# nrf54lc10a_application register map
Vendor: Nordic Semiconductor; Series: nrf54l; File version: 1
CPU: CM33 r0p4, little endian, MPU, FPU, 3 interrupt priority bits, 270 interrupts, 4 SAU regions
Registers are 32-bit, read-write, reset 0x0 unless marked. A register's access mark holds for its fields unless they carry their own. Offsets are from the block's base; [hi:lo] are bit positions; lines under a group give offsets from that group; {n}, {i} and the like mark numbered series; 'fields as' and 'values as' point back to an identical list.

## GLOBAL_FICR_NS — Factory Information Configuration Registers
Base 0x00FFC000
0x300 INFO group — Device info
  0x00 CONFIGID ro reset 0xFFFFFFFF — Configuration identifier
    [15:0] HWID — Identification number for the HW
  {0x4+4j} DEVICEID[{j}] (j=0..1) ro reset 0xFFFFFFFF — Description collection: Device identifier
    [31:0] DEVICEID — 64 bit unique device identifier
  {0xC+4j} UUID[{j}] (j=0..3) ro reset 0xFFFFFFFF — Description collection: 128-bit Universally Unique IDentifier (UUID).
    [31:0] UUID — Device UUID [n].
  0x1C PART ro reset 0xFFFFFFFF — Part code
    [31:0] PART
      0x54BF10A=N54LC10A (nRF54LC10A); 0xFFFFFFFF=Unspecified
  0x20 VARIANT ro reset 0xFFFFFFFF — Function variant code, Hardware version code, and Production configuration code encoded as ASCII.
    [31:0] VARIANT — Function variant code, Hardware version code, and Production configuration code encoded as ASCII
      0x41414230=AAB0 (Example encoding for AAB0 - Function variant code AA, Hardware version code B, Production configuration code 0); 0xFFFFFFFF=Unspecified
  0x24 PACKAGE ro reset 0xFFFFFFFF — Package option
    [31:0] PACKAGE
      0xFFFFFFFF=Unspecified
  0x28 RAM ro reset 0xFFFFFFFF — RAM size (KB)
    [31:0] RAM
      192=K192 (192 kByte RAM); 0xFFFFFFFF=Unspecified
  0x2C RRAM ro reset 0xFFFFFFFF — RRAM size (KB)
    [31:0] RRAM
      0x3F4=K1012 (1012 KByte RRAM); 0xFFFFFFFF=Unspecified
{0x380+4i} ER[{i}] (i=0..3) ro reset 0xFFFFFFFF — Description collection: Common encryption root key, word n
  [31:0] ER — Encryption Root, word n
{0x390+4i} IR[{i}] (i=0..3) ro reset 0xFFFFFFFF — Description collection: Common identity root key, word n
  [31:0] IR — Identity Root, word n
0x3A0 DEVICEADDRTYPE ro reset 0xFFFFFFFF — Device address type
  [0] DEVICEADDRTYPE
    0=Public address; 1=Random address
{0x3A4+4i} DEVICEADDR[{i}] (i=0..1) ro reset 0xFFFFFFFF — Description collection: Device address n
  [31:0] DEVICEADDR — 48 bit device address
{0x400+8i} TRIMCNF[{i}] (i=0..63) group — Unspecified
  0x00 ADDR ro reset 0xFFFFFFFF — Description cluster: Address of the register which will be written
    [31:0] Address
  0x04 DATA ro reset 0xFFFFFFFF — Description cluster: Data to be written into the register
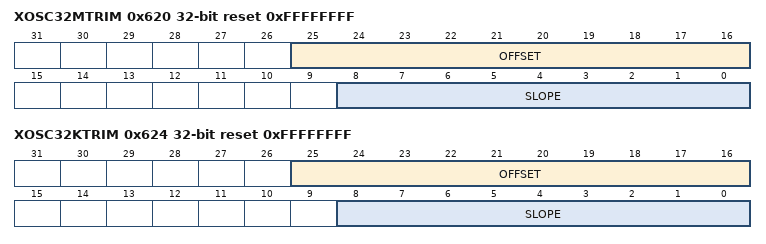
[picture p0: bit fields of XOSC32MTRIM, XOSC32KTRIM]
0x620 XOSC32MTRIM ro reset 0xFFFFFFFF — XOSC32M capacitor selection trim values
  [25:16] OFFSET — Offset trim factor on integer form
  [8:0] SLOPE — Slope trim factor on twos complement form
0x624 XOSC32KTRIM ro reset 0xFFFFFFFF — XOSC32K capacitor selection trim values
  fields as XOSC32MTRIM

## ICACHEDATA_S — CACHEDATA
Base 0x02F00000
{0x0+0x40*i} SET[{i}] (i=0..127) group — Unspecified
  {0x0+0x20*j} WAY[{j}] (j=0..1) group — Unspecified
    {0x0+8k} DU[{k}] (k=0..3) group — Unspecified
      {0x0+4l} DATA[{l}] (l=0..1) — Description collection: Cache data bits for DATA[q] in DU[p] (DataUnit) of SET[n], WAY[o].
        [31:0] Data ro

## ICACHEINFO_S — CACHEINFO
Base 0x02F10000
{0x0+8i} SET[{i}] (i=0..127) group — Unspecified
  {0x0+4j} WAY[{j}] (j=0..1) group — Unspecified
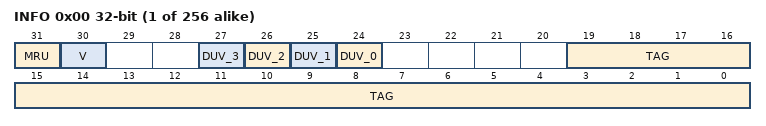
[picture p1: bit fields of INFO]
    0x00 INFO — Description cluster: Cache information for SET[n], WAY[o].
      [31] MRU ro — Most recently used way.
        0=Way0 was most recently used; 1=Way1 was most recently used
      [30] V ro — Line valid bit.
        0=Invalid cache line; 1=Valid cache line
      [n+24] DUV_{n} ro (n=0..3) — Data unit valid info.
        0=Invalid data unit; 1=Valid data unit
      [19:0] TAG ro — Cache tag.

## ICACHE_S — Cache
Base 0xE0082000
0x08 TASKS_INVALIDATECACHE wo — Invalidate the cache.
  [0] TASKS_INVALIDATECACHE
    1=Trigger task
0x14 TASKS_INVALIDATELINE wo — Invalidate the line.
  [0] TASKS_INVALIDATELINE
    1=Trigger task
0x20 TASKS_ERASE wo — Erase the cache.
  [0] TASKS_ERASE
    1=Trigger task
0x400 STATUS ro — Status of the cache activities.
  [0] READY — Ready status.
    0=Ready (Activity is done and ready for the next activity.); 1=Busy (Activity is in progress.)
0x404 ENABLE — Enable cache.
  [0] ENABLE — Enable cache
    0=Disabled (Disable cache); 1=Enabled (Enable cache)
0x410 LINEADDR — Memory address covered by the line to be maintained.
  [31:0] ADDR — Address.
0x414 PROFILING group — Unspecified
  0x00 ENABLE — Enable the profiling counters.
    [0] ENABLE — Enable the profiling counters
      0=Disable profiling; 1=Enable profiling
  0x04 CLEAR wo — Clear the profiling counters.
    [0] CLEAR — Clearing the profiling counters
      1=Clear the profiling counters
  0x08 HIT ro — The cache hit counter for cache region.
    [31:0] HITS — Number of cache hits
  0x0C MISS ro — The cache miss counter for cache region.
    [31:0] MISSES — Number of cache misses
  0x10 LMISS ro — The cache line miss counter for cache region.
    [31:0] LMISSES — Number of cache line misses
  0x14 READS ro — Number of reads for cache region.
  0x18 WRITES ro — Number of writes for cache region.
0x430 DEBUGLOCK rw-once — Lock debug mode.
  [0] DEBUGLOCK — Lock debug mode
    0=Unlocked (Debug mode unlocked); 1=Locked (Debug mode locked. Ignores any other value written.)
0x434 WRITELOCK — Lock cache updates.
  [0] WRITELOCK — Lock cache updates
    0=Unlocked (Cache updates unlocked); 1=Locked (Cache updates locked)

## Notices in the file
Copyright (c) 2010 - 2026, Nordic Semiconductor ASA All rights reserved.
SPDX-License-Identifier: BSD-3-Clause
Redistribution and use in source and binary forms, with or without
modification, are permitted provided that the following conditions are met:
1. Redistributions of source code must retain the above copyright notice, this
list of conditions and the following disclaimer.
2. Redistributions in binary form must reproduce the above copyright
notice, this list of conditions and the following disclaimer in the
documentation and/or other materials provided with the distribution.
3. Neither the name of Nordic Semiconductor ASA nor the names of its
contributors may be used to endorse or promote products derived from this
software without specific prior written permission.
THIS SOFTWARE IS PROVIDED BY THE COPYRIGHT HOLDERS AND CONTRIBUTORS "AS IS"
AND ANY EXPRESS OR IMPLIED WARRANTIES, INCLUDING, BUT NOT LIMITED TO, THE
IMPLIED WARRANTIES OF MERCHANTABILITY, AND FITNESS FOR A PARTICULAR PURPOSE
ARE DISCLAIMED. IN NO EVENT SHALL NORDIC SEMICONDUCTOR ASA OR CONTRIBUTORS BE
LIABLE FOR ANY DIRECT, INDIRECT, INCIDENTAL, SPECIAL, EXEMPLARY, OR
CONSEQUENTIAL DAMAGES (INCLUDING, BUT NOT LIMITED TO, PROCUREMENT OF
SUBSTITUTE GOODS OR SERVICES; LOSS OF USE, DATA, OR PROFITS; OR BUSINESS
INTERRUPTION) HOWEVER CAUSED AND ON ANY THEORY OF LIABILITY, WHETHER IN
CONTRACT, STRICT LIABILITY, OR TORT (INCLUDING NEGLIGENCE OR OTHERWISE)
ARISING IN ANY WAY OUT OF THE USE OF THIS SOFTWARE, EVEN IF ADVISED OF THE
POSSIBILITY OF SUCH DAMAGE.
